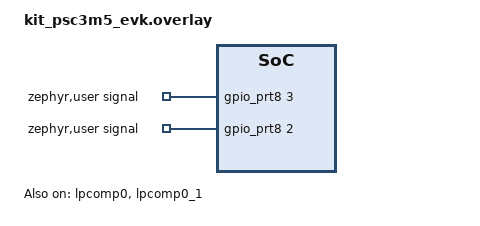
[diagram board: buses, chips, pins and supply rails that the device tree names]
/*
 * Copyright (c) 2026 Infineon Technologies AG,
 * or an affiliate of Infineon Technologies AG.
 *
 * SPDX-License-Identifier: Apache-2.0
 */

/ {
	zephyr,user {
		signal-gpios = <&gpio_prt8 3 0>, <&gpio_prt8 2 0>;
	};
};

&gpio_prt8 {
	status = "okay";
};

&lpcomp0 {
	status = "okay";
};

&lpcomp0_0 {
	status = "disabled";
	output-mode = "direct";
	power = "ulp";
	intr-type = "both";
	input-p = "gpio";
	input-n = "local_vref";
};

&lpcomp0_1 {
	status = "okay";
	output-mode = "direct";
	power = "ulp";
	intr-type = "both";
	input-p = "gpio";
	input-n = "local_vref";
};
